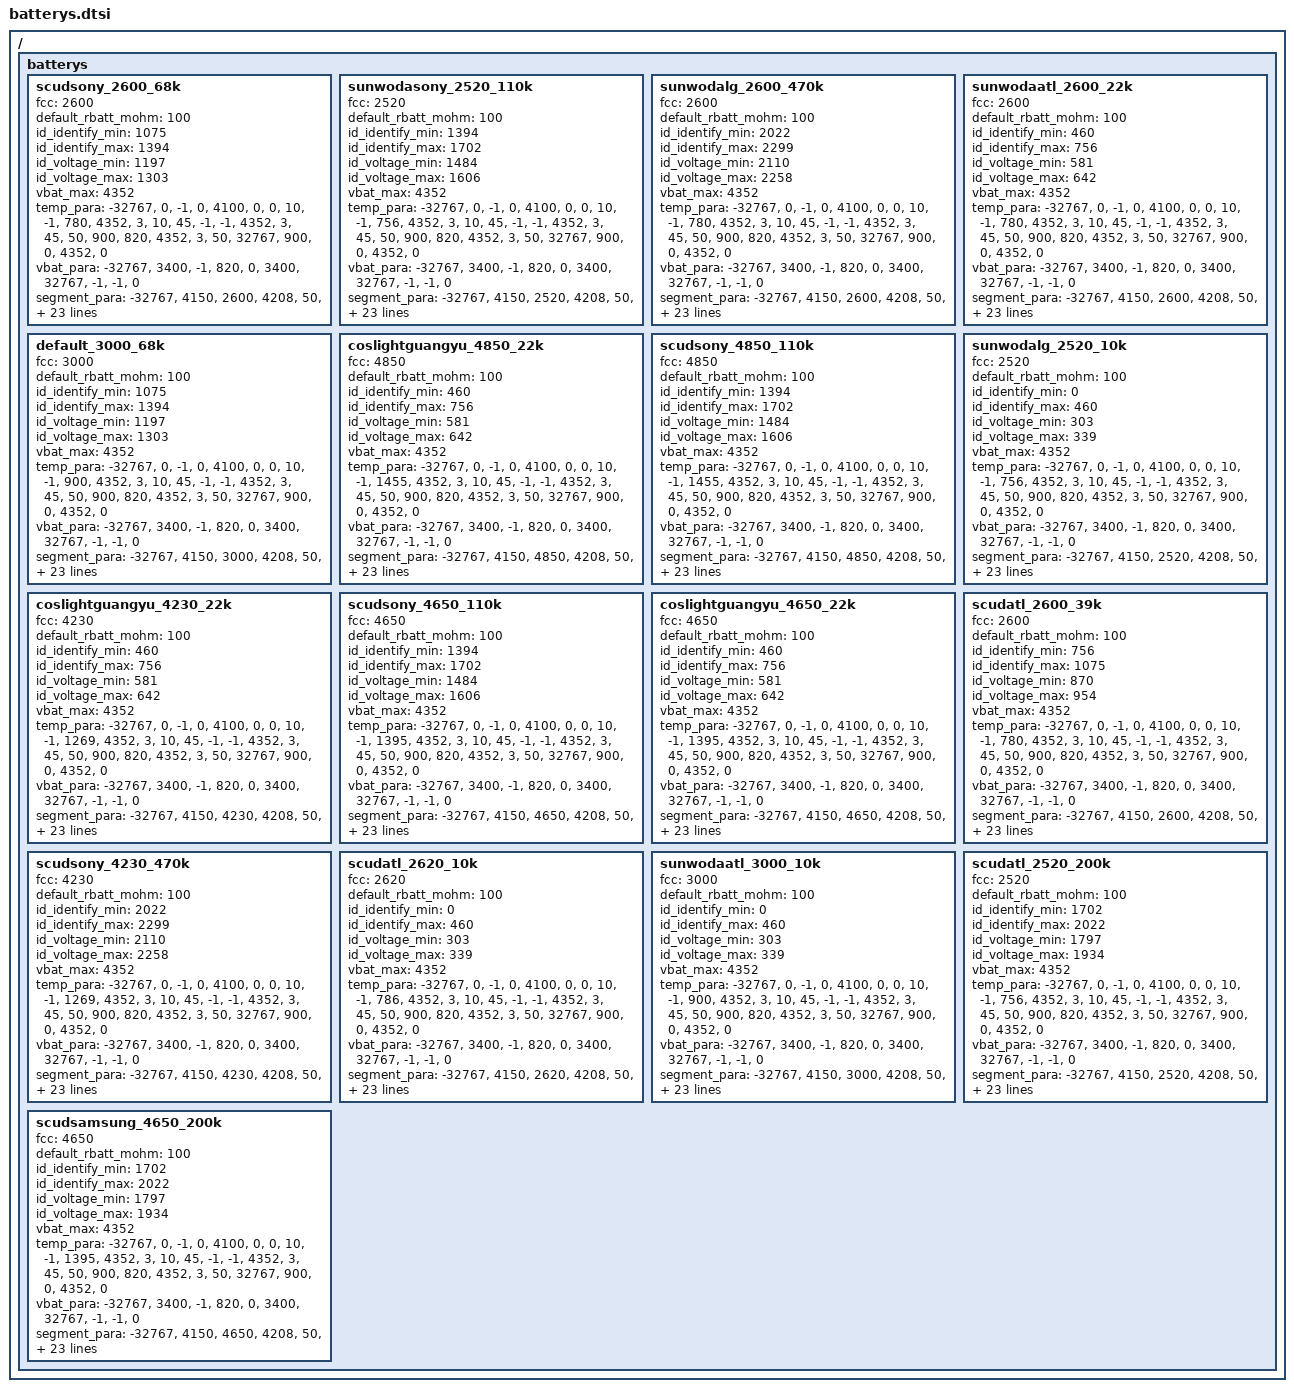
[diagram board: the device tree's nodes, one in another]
/* DO NOT EDIT - Automatically generated by python */
/ {
	batterys:batterys {
		scudsony_2600_68k:scudsony_2600_68k {
			fcc = <2600>;
			default_rbatt_mohm = <100>;
			id_identify_min = <1075>;
			id_identify_max = <1394>;
			id_voltage_min = <1197>;
			id_voltage_max = <1303>;
			vbat_max = <4352>;
			temp_para = 
						"-32767","0","-1","0","4100","0",
						"0","10","-1","780","4352","3",
						"10","45","-1","-1","4352","3",
						"45","50","900","820","4352","3",
						"50","32767","900","0","4352","0";
			vbat_para = 
						"-32767","3400","-1","820","0",
						"3400","32767","-1","-1","0";
			segment_para = 
						"-32767","4150","2600","4208","50",
						"4150","4450","1300","4352","0";
			batt_brand = "scudsony";
			fcc_temp = <2601 2604 2617 2680 2656 2621>;
			fcc_sf_x = <0 100 200 300 400 500>;
			fcc_sf_y = <100 96 94 92 90 88>;
			fcc_sf_cols = <6>;
			pc_sf_rows = <1>;
			pc_sf_cols = <1>;
			pc_sf_row_entries = <0>;
			pc_sf_percent = <100>;
			pc_sf_sf = <100>;
			rbatt_sf_rows = <28>;
			rbatt_sf_cols = <6>;
			rbatt_sf_percent = <100 95 90 85 80 75 70 65 60 55 50 45 40 35 30 25 20 15 10 9 8 7 6 5 4 3 2 1>;
			rbatt_sf_sf = <
			               1652 745 382 153 115 102
			               1652 746 382 154 116 102
			               1683 784 409 162 119 104
			               1668 786 433 171 123 106
			               1701 791 451 182 128 108
			               1666 773 463 194 135 111
			               1674 761 425 212 144 117
			               1691 774 416 218 157 124
			               1736 790 408 188 156 132
			               1790 809 404 166 129 109
			               1840 839 416 159 119 106
			               1922 860 435 164 121 107
			               2023 879 454 170 126 109
			               2134 923 475 175 132 113
			               2297 968 502 177 131 111
			               2515 1031 529 174 123 107
			               2838 1102 548 170 122 107
			               3317 1307 595 167 122 107
			               4148 1778 633 167 121 108
			               4298 1645 624 170 120 107
			               4906 1788 635 178 121 107
			               5835 2015 680 175 122 110
			               7110 2305 732 181 125 108
			               9342 2860 829 181 125 110
			               15676 4001 931 191 127 109
			               37262 7035 1267 216 132 106
			               79489 30656 1984 342 146 112
			               124988 50688 5514 592 295 122
			              >;
			pc_temp_ocv_rows = <29>;
			pc_temp_ocv_cols = <6>;
			pc_temp_ocv_percent = <100 95 90 85 80 75 70 65 60 55 50 45 40 35 30 25 20 15 10 9 8 7 6 5 4 3 2 1>;
			pc_temp_ocv_ocv = <
			                   4332 4326 4324 4319 4309 4303
			                   4244 4250 4255 4256 4247 4244
			                   4175 4191 4198 4199 4191 4189
			                   4109 4130 4143 4144 4137 4136
			                   4057 4075 4090 4093 4086 4086
			                   3993 4019 4039 4044 4039 4039
			                   3938 3967 3982 3999 3996 3997
			                   3888 3924 3938 3954 3955 3957
			                   3846 3885 3898 3907 3913 3916
			                   3811 3851 3863 3868 3870 3871
			                   3781 3823 3834 3839 3840 3842
			                   3760 3797 3811 3817 3818 3820
			                   3744 3775 3791 3799 3801 3801
			                   3728 3763 3775 3783 3786 3785
			                   3714 3751 3763 3768 3768 3765
			                   3698 3735 3749 3750 3745 3735
			                   3683 3705 3726 3728 3722 3712
			                   3665 3672 3694 3695 3692 3683
			                   3637 3650 3658 3670 3667 3658
			                   3629 3644 3654 3665 3663 3655
			                   3616 3637 3649 3660 3658 3651
			                   3604 3627 3642 3652 3651 3645
			                   3588 3613 3631 3640 3639 3632
			                   3565 3593 3614 3613 3610 3600
			                   3536 3563 3577 3569 3565 3557
			                   3489 3508 3523 3511 3508 3502
			                   3417 3429 3446 3442 3436 3432
			                   3321 3320 3345 3354 3342 3337
			                   3200 3200 3200 3200 3200 3200
			                  >;
		};
		sunwodasony_2520_110k:sunwodasony_2520_110k {
			fcc = <2520>;
			default_rbatt_mohm = <100>;
			id_identify_min = <1394>;
			id_identify_max = <1702>;
			id_voltage_min = <1484>;
			id_voltage_max = <1606>;
			vbat_max = <4352>;
			temp_para = 
						"-32767","0","-1","0","4100","0",
						"0","10","-1","756","4352","3",
						"10","45","-1","-1","4352","3",
						"45","50","900","820","4352","3",
						"50","32767","900","0","4352","0";
			vbat_para = 
						"-32767","3400","-1","820","0",
						"3400","32767","-1","-1","0";
			segment_para = 
						"-32767","4150","2520","4208","50",
						"4150","4450","1260","4352","0";
			batt_brand = "sunwodasony";
			fcc_temp = <2508 2496 2507 2552 2518 2497>;
			fcc_sf_x = <0 100 200 300 400 500>;
			fcc_sf_y = <100 96 94 92 90 88>;
			fcc_sf_cols = <6>;
			pc_sf_rows = <1>;
			pc_sf_cols = <1>;
			pc_sf_row_entries = <0>;
			pc_sf_percent = <100>;
			pc_sf_sf = <100>;
			rbatt_sf_rows = <28>;
			rbatt_sf_cols = <6>;
			rbatt_sf_percent = <100 95 90 85 80 75 70 65 60 55 50 45 40 35 30 25 20 15 10 9 8 7 6 5 4 3 2 1>;
			rbatt_sf_sf = <
			               1431 634 335 135 107 96
			               1431 634 335 135 107 96
			               1446 667 357 142 111 98
			               1443 684 380 150 115 99
			               1460 706 409 161 120 101
			               1403 664 424 176 125 104
			               1408 633 386 189 134 109
			               1445 634 367 194 152 119
			               1477 632 351 166 145 120
			               1485 661 344 144 117 103
			               1572 694 350 140 112 99
			               1658 732 367 143 114 100
			               1752 758 387 148 117 102
			               1856 778 405 153 123 105
			               1986 801 429 152 119 100
			               2149 837 452 149 113 100
			               2401 842 448 144 112 100
			               2790 999 435 143 112 100
			               3596 1377 527 150 113 100
			               3742 1363 527 143 114 100
			               3881 1236 529 141 113 102
			               4020 1317 546 145 118 103
			               3962 1387 558 146 117 100
			               4692 1499 564 145 112 100
			               5804 1635 574 149 115 101
			               7150 1955 606 151 116 103
			               9204 2435 686 159 116 104
			               12389 3390 819 171 123 113
			              >;
			pc_temp_ocv_rows = <29>;
			pc_temp_ocv_cols = <6>;
			pc_temp_ocv_percent = <100 95 90 85 80 75 70 65 60 55 50 45 40 35 30 25 20 15 10 9 8 7 6 5 4 3 2 1>;
			pc_temp_ocv_ocv = <
			                   4337 4323 4320 4325 4310 4303
			                   4261 4257 4257 4265 4250 4245
			                   4195 4199 4201 4209 4195 4191
			                   4134 4143 4146 4155 4142 4138
			                   4083 4092 4095 4102 4092 4088
			                   4016 4031 4046 4054 4045 4042
			                   3960 3977 3989 4006 4002 3999
			                   3915 3933 3942 3961 3962 3960
			                   3873 3891 3902 3914 3917 3916
			                   3828 3858 3867 3876 3873 3873
			                   3796 3830 3837 3847 3845 3844
			                   3771 3807 3814 3824 3823 3822
			                   3753 3787 3795 3805 3804 3803
			                   3738 3770 3779 3789 3789 3787
			                   3727 3756 3768 3772 3771 3761
			                   3716 3743 3757 3755 3747 3735
			                   3706 3714 3734 3732 3725 3713
			                   3691 3695 3700 3703 3694 3681
			                   3661 3676 3676 3678 3672 3662
			                   3658 3670 3671 3675 3669 3658
			                   3656 3661 3667 3671 3666 3655
			                   3654 3652 3661 3665 3660 3648
			                   3628 3638 3650 3653 3646 3631
			                   3597 3615 3626 3625 3615 3598
			                   3561 3576 3586 3581 3571 3555
			                   3510 3523 3532 3525 3516 3501
			                   3441 3451 3462 3454 3446 3432
			                   3345 3356 3365 3356 3350 3339
			                   3200 3200 3200 3200 3200 3200
			                  >;
		};
		sunwodalg_2600_470k:sunwodalg_2600_470k {
			fcc = <2600>;
			default_rbatt_mohm = <100>;
			id_identify_min = <2022>;
			id_identify_max = <2299>;
			id_voltage_min = <2110>;
			id_voltage_max = <2258>;
			vbat_max = <4352>;
			temp_para = 
						"-32767","0","-1","0","4100","0",
						"0","10","-1","780","4352","3",
						"10","45","-1","-1","4352","3",
						"45","50","900","820","4352","3",
						"50","32767","900","0","4352","0";
			vbat_para = 
						"-32767","3400","-1","820","0",
						"3400","32767","-1","-1","0";
			segment_para = 
						"-32767","4150","2600","4208","50",
						"4150","4450","1300","4352","0";
			batt_brand = "sunwodalg";
			fcc_temp = <2702 2691 2691 2724 2698 2680>;
			fcc_sf_x = <0 100 200 300 400 500>;
			fcc_sf_y = <100 96 94 92 90 88>;
			fcc_sf_cols = <6>;
			pc_sf_rows = <1>;
			pc_sf_cols = <1>;
			pc_sf_row_entries = <0>;
			pc_sf_percent = <100>;
			pc_sf_sf = <100>;
			rbatt_sf_rows = <28>;
			rbatt_sf_cols = <6>;
			rbatt_sf_percent = <100 95 90 85 80 75 70 65 60 55 50 45 40 35 30 25 20 15 10 9 8 7 6 5 4 3 2 1>;
			rbatt_sf_sf = <
			               2513 1705 766 152 108 91
			               2507 1700 766 152 108 91
			               2386 1589 761 155 110 93
			               2309 1510 759 161 114 95
			               2278 1493 780 168 118 97
			               2200 1433 792 176 124 100
			               2196 1411 780 190 130 104
			               2196 1407 790 211 143 110
			               2218 1409 771 206 153 120
			               2261 1428 766 169 134 115
			               2323 1469 790 154 112 94
			               2406 1530 838 158 114 96
			               2501 1609 904 164 121 101
			               2617 1699 986 170 127 106
			               2759 1806 1082 175 123 101
			               2933 1927 1191 178 118 94
			               3161 2055 1322 179 118 96
			               3477 2238 1484 180 116 94
			               7285 3492 1756 188 122 98
			               7742 3763 1907 189 120 98
			               8270 4120 2106 198 124 99
			               8805 4434 2276 209 127 100
			               9397 4816 2552 219 127 99
			               10043 5214 2774 253 128 100
			               10774 5548 3094 491 142 104
			               11603 6041 3283 736 297 196
			               12596 6698 3576 549 371 166
			               13951 7437 4010 582 217 108
			              >;
			pc_temp_ocv_rows = <29>;
			pc_temp_ocv_cols = <6>;
			pc_temp_ocv_percent = <100 95 90 85 80 75 70 65 60 55 50 45 40 35 30 25 20 15 10 9 8 7 6 5 4 3 2 1>;
			pc_temp_ocv_ocv = <
			                   4334 4328 4325 4321 4310 4304
			                   4241 4242 4246 4258 4248 4245
			                   4174 4176 4183 4202 4192 4191
			                   4113 4119 4127 4148 4139 4138
			                   4057 4071 4077 4097 4088 4088
			                   3988 4009 4026 4049 4041 4040
			                   3939 3957 3975 4003 3998 3997
			                   3897 3914 3933 3964 3959 3958
			                   3864 3875 3887 3919 3919 3921
			                   3838 3844 3849 3872 3874 3878
			                   3820 3823 3823 3839 3838 3839
			                   3804 3807 3805 3816 3815 3816
			                   3792 3796 3794 3797 3798 3797
			                   3779 3786 3784 3782 3782 3782
			                   3765 3775 3774 3770 3767 3761
			                   3750 3760 3758 3756 3750 3738
			                   3735 3737 3737 3733 3729 3716
			                   3714 3714 3709 3692 3691 3682
			                   3682 3687 3680 3681 3675 3664
			                   3674 3681 3675 3679 3673 3662
			                   3667 3677 3669 3675 3671 3660
			                   3657 3671 3660 3668 3667 3657
			                   3643 3662 3650 3650 3658 3647
			                   3622 3646 3634 3614 3632 3620
			                   3590 3615 3611 3575 3589 3580
			                   3545 3568 3568 3533 3541 3532
			                   3478 3502 3500 3460 3478 3465
			                   3379 3400 3398 3348 3374 3364
			                   3200 3200 3200 3200 3200 3200
			                  >;
		};
		sunwodaatl_2600_22k:sunwodaatl_2600_22k {
			fcc = <2600>;
			default_rbatt_mohm = <100>;
			id_identify_min = <460>;
			id_identify_max = <756>;
			id_voltage_min = <581>;
			id_voltage_max = <642>;
			vbat_max = <4352>;
			temp_para = 
						"-32767","0","-1","0","4100","0",
						"0","10","-1","780","4352","3",
						"10","45","-1","-1","4352","3",
						"45","50","900","820","4352","3",
						"50","32767","900","0","4352","0";
			vbat_para = 
						"-32767","3400","-1","820","0",
						"3400","32767","-1","-1","0";
			segment_para = 
						"-32767","4150","2600","4208","50",
						"4150","4450","1300","4352","0";
			batt_brand = "sunwodaatl";
			fcc_temp = <2647 2638 2645 2649 2642 2628>;
			fcc_sf_x = <0 100 200 300 400 500>;
			fcc_sf_y = <100 96 94 92 90 88>;
			fcc_sf_cols = <6>;
			pc_sf_rows = <1>;
			pc_sf_cols = <1>;
			pc_sf_row_entries = <0>;
			pc_sf_percent = <100>;
			pc_sf_sf = <100>;
			rbatt_sf_rows = <28>;
			rbatt_sf_cols = <6>;
			rbatt_sf_percent = <100 95 90 85 80 75 70 65 60 55 50 45 40 35 30 25 20 15 10 9 8 7 6 5 4 3 2 1>;
			rbatt_sf_sf = <
			               2648 1691 662 174 126 104
			               2646 1690 663 174 126 104
			               2521 1634 677 177 127 105
			               2409 1568 686 181 129 106
			               2359 1550 703 187 132 108
			               2271 1473 719 195 137 110
			               2266 1449 691 208 143 115
			               2255 1439 690 227 155 120
			               2263 1437 671 222 164 128
			               2291 1448 661 182 136 110
			               2336 1481 671 169 124 106
			               2406 1528 697 171 125 105
			               2497 1595 738 176 129 109
			               2612 1679 795 181 136 114
			               2761 1783 866 183 135 114
			               2943 1918 952 184 125 104
			               3183 2072 1070 185 127 105
			               3541 2275 1254 191 130 106
			               6783 2928 1296 197 134 109
			               7566 3253 1404 198 133 110
			               8348 3606 1549 204 135 110
			               9164 4006 1722 218 137 111
			               10138 4535 1956 222 142 113
			               11173 5084 2218 224 143 112
			               12392 5727 2544 227 141 111
			               13841 6531 2941 248 148 111
			               15742 7595 3512 304 159 114
			               16534 9284 4272 677 220 173
			              >;
			pc_temp_ocv_rows = <29>;
			pc_temp_ocv_cols = <6>;
			pc_temp_ocv_percent = <100 95 90 85 80 75 70 65 60 55 50 45 40 35 30 25 20 15 10 9 8 7 6 5 4 3 2 1>;
			pc_temp_ocv_ocv = <
			                   4330 4323 4322 4317 4310 4303
			                   4233 4237 4246 4252 4246 4241
			                   4163 4172 4185 4195 4190 4184
			                   4099 4112 4130 4140 4135 4130
			                   4042 4062 4078 4088 4083 4078
			                   3975 3997 4027 4040 4036 4030
			                   3931 3949 3973 3994 3991 3987
			                   3890 3908 3931 3955 3952 3947
			                   3857 3871 3889 3911 3912 3909
			                   3831 3841 3852 3864 3864 3860
			                   3812 3819 3823 3833 3833 3831
			                   3798 3803 3803 3812 3811 3809
			                   3786 3792 3790 3794 3794 3791
			                   3774 3783 3781 3780 3779 3777
			                   3761 3773 3771 3767 3765 3760
			                   3746 3759 3758 3752 3745 3732
			                   3730 3737 3738 3732 3724 3711
			                   3709 3710 3709 3702 3697 3685
			                   3678 3683 3675 3676 3670 3659
			                   3670 3677 3670 3673 3667 3656
			                   3662 3671 3666 3670 3664 3653
			                   3651 3664 3660 3664 3660 3648
			                   3640 3656 3652 3655 3653 3640
			                   3623 3642 3636 3634 3636 3620
			                   3598 3617 3605 3592 3597 3581
			                   3559 3571 3553 3535 3543 3527
			                   3498 3503 3482 3459 3472 3456
			                   3400 3402 3374 3359 3373 3355
			                   3200 3200 3200 3200 3200 3200
			                  >;
		};
		default_3000_68k:default_3000_68k {
			fcc = <3000>;
			default_rbatt_mohm = <100>;
			id_identify_min = <1075>;
			id_identify_max = <1394>;
			id_voltage_min = <1197>;
			id_voltage_max = <1303>;
			vbat_max = <4352>;
			temp_para = 
						"-32767","0","-1","0","4100","0",
						"0","10","-1","900","4352","3",
						"10","45","-1","-1","4352","3",
						"45","50","900","820","4352","3",
						"50","32767","900","0","4352","0";
			vbat_para = 
						"-32767","3400","-1","820","0",
						"3400","32767","-1","-1","0";
			segment_para = 
						"-32767","4150","3000","4208","50",
						"4150","4450","1500","4352","0";
			batt_brand = "default";
			fcc_temp = <3007 3010 3005 3022 3018 2996>;
			fcc_sf_x = <0 100 200 300 400 500>;
			fcc_sf_y = <100 96 94 92 90 88>;
			fcc_sf_cols = <6>;
			pc_sf_rows = <1>;
			pc_sf_cols = <1>;
			pc_sf_row_entries = <0>;
			pc_sf_percent = <100>;
			pc_sf_sf = <100>;
			rbatt_sf_rows = <28>;
			rbatt_sf_cols = <6>;
			rbatt_sf_percent = <100 95 90 85 80 75 70 65 60 55 50 45 40 35 30 25 20 15 10 9 8 7 6 5 4 3 2 1>;
			rbatt_sf_sf = <
			               1971 888 459 150 121 112
			               1970 888 459 150 121 112
			               1839 913 472 152 123 113
			               1713 920 490 156 125 115
			               1676 943 504 161 128 116
			               1543 895 532 170 132 118
			               1517 837 489 181 137 121
			               1515 831 470 199 148 127
			               1516 824 448 200 160 137
			               1531 823 437 155 129 116
			               1611 847 434 150 123 114
			               1714 921 422 151 124 115
			               1830 1023 448 155 128 117
			               1954 1148 499 158 134 120
			               2083 1284 576 159 132 122
			               2230 1422 664 157 125 114
			               2410 1589 766 154 122 113
			               2657 1792 883 159 123 113
			               3658 1996 983 161 128 117
			               4481 2141 924 161 129 119
			               4966 2392 991 159 127 116
			               5434 2660 1095 166 127 116
			               5970 2933 1229 168 130 118
			               6541 3252 1382 172 129 118
			               7189 3594 1509 175 129 117
			               7980 3994 1669 183 132 119
			               8915 4511 1946 202 136 120
			               10198 5252 2365 279 143 122
			              >;
			pc_temp_ocv_rows = <29>;
			pc_temp_ocv_cols = <6>;
			pc_temp_ocv_percent = <100 95 90 85 80 75 70 65 60 55 50 45 40 35 30 25 20 15 10 9 8 7 6 5 4 3 2 1>;
			pc_temp_ocv_ocv = <
			                   4326 4325 4322 4317 4311 4305
			                   4224 4239 4246 4254 4249 4245
			                   4156 4178 4186 4196 4193 4189
			                   4090 4121 4132 4142 4138 4134
			                   4041 4073 4082 4090 4086 4083
			                   3967 4011 4034 4042 4038 4035
			                   3917 3951 3976 3997 3994 3991
			                   3878 3907 3929 3957 3955 3952
			                   3843 3868 3885 3914 3915 3914
			                   3815 3833 3849 3865 3865 3863
			                   3801 3808 3821 3835 3835 3834
			                   3788 3796 3797 3813 3812 3812
			                   3774 3786 3785 3794 3794 3793
			                   3760 3776 3777 3779 3780 3778
			                   3746 3761 3768 3767 3765 3762
			                   3732 3740 3753 3754 3747 3737
			                   3716 3720 3730 3734 3726 3716
			                   3699 3702 3700 3705 3699 3688
			                   3671 3684 3677 3680 3674 3664
			                   3662 3677 3673 3679 3672 3662
			                   3653 3671 3669 3677 3671 3660
			                   3640 3664 3664 3673 3668 3657
			                   3626 3654 3658 3667 3663 3652
			                   3606 3637 3645 3650 3650 3638
			                   3578 3609 3618 3611 3614 3604
			                   3540 3566 3571 3554 3560 3553
			                   3482 3500 3502 3478 3490 3486
			                   3389 3399 3403 3363 3387 3387
			                   3200 3200 3200 3200 3200 3200
			                  >;
		};
		coslightguangyu_4850_22k:coslightguangyu_4850_22k {
			fcc = <4850>;
			default_rbatt_mohm = <100>;
			id_identify_min = <460>;
			id_identify_max = <756>;
			id_voltage_min = <581>;
			id_voltage_max = <642>;
			vbat_max = <4352>;
			temp_para = 
						"-32767","0","-1","0","4100","0",
						"0","10","-1","1455","4352","3",
						"10","45","-1","-1","4352","3",
						"45","50","900","820","4352","3",
						"50","32767","900","0","4352","0";
			vbat_para = 
						"-32767","3400","-1","820","0",
						"3400","32767","-1","-1","0";
			segment_para = 
						"-32767","4150","4850","4208","50",
						"4150","4450","2425","4352","0";
			batt_brand = "coslightguangyu";
			fcc_temp = <5059 5069 5068 5086 5083 5045>;
			fcc_sf_x = <0 100 200 300 400 500>;
			fcc_sf_y = <100 96 94 92 90 88>;
			fcc_sf_cols = <6>;
			pc_sf_rows = <1>;
			pc_sf_cols = <1>;
			pc_sf_row_entries = <0>;
			pc_sf_percent = <100>;
			pc_sf_sf = <100>;
			rbatt_sf_rows = <28>;
			rbatt_sf_cols = <6>;
			rbatt_sf_percent = <100 95 90 85 80 75 70 65 60 55 50 45 40 35 30 25 20 15 10 9 8 7 6 5 4 3 2 1>;
			rbatt_sf_sf = <
			               1395 696 333 119 103 102
			               1391 696 333 119 103 102
			               1297 699 339 119 104 103
			               1210 694 343 121 105 103
			               1178 699 348 124 106 104
			               1053 677 378 129 108 105
			               1008 586 313 132 111 107
			               1000 597 303 133 112 108
			               988 591 302 120 105 104
			               1011 597 298 116 104 103
			               1051 633 298 117 104 103
			               1098 687 307 118 104 104
			               1148 751 330 121 106 104
			               1200 820 366 123 107 106
			               1257 893 412 119 105 104
			               1324 963 464 117 104 103
			               1406 1039 531 120 104 103
			               1505 1132 624 122 105 104
			               2041 1001 494 119 105 105
			               2186 1079 529 120 106 105
			               2309 1154 568 121 107 107
			               2488 1257 615 121 107 107
			               2671 1370 664 120 107 104
			               2887 1496 718 121 105 105
			               3140 1643 783 123 107 105
			               3461 1863 883 126 108 105
			               3883 2147 1062 142 111 109
			               4391 2470 1282 243 143 126
			              >;
			pc_temp_ocv_rows = <29>;
			pc_temp_ocv_cols = <6>;
			pc_temp_ocv_percent = <100 95 90 85 80 75 70 65 60 55 50 45 40 35 30 25 20 15 10 9 8 7 6 5 4 3 2 1>;
			pc_temp_ocv_ocv = <
			                   4342 4341 4338 4332 4328 4322
			                   4241 4255 4262 4271 4268 4264
			                   4174 4191 4203 4213 4211 4207
			                   4111 4136 4150 4158 4156 4153
			                   4067 4087 4098 4106 4102 4100
			                   3980 4028 4051 4057 4051 4050
			                   3924 3943 3969 3995 4000 4003
			                   3884 3903 3922 3949 3955 3956
			                   3845 3863 3885 3903 3905 3905
			                   3820 3830 3850 3868 3868 3869
			                   3804 3810 3821 3840 3841 3841
			                   3790 3797 3801 3818 3818 3818
			                   3776 3785 3787 3799 3800 3799
			                   3763 3773 3777 3782 3783 3781
			                   3750 3759 3765 3765 3760 3754
			                   3736 3742 3750 3748 3739 3729
			                   3721 3723 3731 3729 3722 3710
			                   3701 3709 3707 3705 3698 3687
			                   3672 3690 3688 3688 3681 3670
			                   3662 3685 3685 3686 3679 3668
			                   3649 3677 3680 3684 3677 3666
			                   3634 3666 3672 3678 3672 3662
			                   3616 3649 3658 3664 3657 3649
			                   3592 3624 3633 3632 3627 3619
			                   3561 3588 3596 3591 3586 3579
			                   3520 3542 3545 3538 3535 3530
			                   3466 3480 3479 3470 3468 3466
			                   3379 3384 3384 3379 3372 3375
			                   3200 3200 3200 3200 3200 3200
			                  >;
		};
		scudsony_4850_110k:scudsony_4850_110k {
			fcc = <4850>;
			default_rbatt_mohm = <100>;
			id_identify_min = <1394>;
			id_identify_max = <1702>;
			id_voltage_min = <1484>;
			id_voltage_max = <1606>;
			vbat_max = <4352>;
			temp_para = 
						"-32767","0","-1","0","4100","0",
						"0","10","-1","1455","4352","3",
						"10","45","-1","-1","4352","3",
						"45","50","900","820","4352","3",
						"50","32767","900","0","4352","0";
			vbat_para = 
						"-32767","3400","-1","820","0",
						"3400","32767","-1","-1","0";
			segment_para = 
						"-32767","4150","4850","4208","50",
						"4150","4450","2425","4352","0";
			batt_brand = "scudsony";
			fcc_temp = <4975 4906 4919 4975 4952 4965>;
			fcc_sf_x = <0 100 200 300 400 500>;
			fcc_sf_y = <100 96 94 92 90 88>;
			fcc_sf_cols = <6>;
			pc_sf_rows = <1>;
			pc_sf_cols = <1>;
			pc_sf_row_entries = <0>;
			pc_sf_percent = <100>;
			pc_sf_sf = <100>;
			rbatt_sf_rows = <28>;
			rbatt_sf_cols = <6>;
			rbatt_sf_percent = <100 95 90 85 80 75 70 65 60 55 50 45 40 35 30 25 20 15 10 9 8 7 6 5 4 3 2 1>;
			rbatt_sf_sf = <
			               1377 867 425 128 90 80
			               1376 867 425 128 90 80
			               1339 878 433 130 91 81
			               1301 879 438 132 93 81
			               1275 871 446 137 95 83
			               1256 856 452 143 98 84
			               1249 849 448 151 103 86
			               1251 842 442 154 109 90
			               1266 856 442 144 105 91
			               1283 876 442 135 94 84
			               1311 892 451 133 94 83
			               1342 923 470 136 96 85
			               1380 947 498 142 98 86
			               1434 977 521 146 101 87
			               1502 1018 550 149 101 87
			               1596 1077 577 149 99 86
			               1729 1145 612 150 99 87
			               1940 1249 666 155 100 87
			               3752 1781 773 150 102 87
			               4074 1920 806 151 101 88
			               4439 2049 844 152 102 90
			               4911 2222 895 154 103 89
			               5585 2450 980 157 104 88
			               6486 2695 1068 157 103 88
			               7511 3049 1155 157 104 91
			               8846 3580 1315 163 107 90
			               10180 4481 1557 176 109 93
			               11515 5722 1971 192 119 100
			              >;
			pc_temp_ocv_rows = <29>;
			pc_temp_ocv_cols = <6>;
			pc_temp_ocv_percent = <100 95 90 85 80 75 70 65 60 55 50 45 40 35 30 25 20 15 10 9 8 7 6 5 4 3 2 1>;
			pc_temp_ocv_ocv = <
			                   4337 4336 4334 4325 4318 4323
			                   4219 4230 4246 4253 4250 4256
			                   4145 4166 4183 4195 4193 4199
			                   4080 4108 4126 4141 4140 4146
			                   4019 4051 4074 4090 4089 4095
			                   3964 3994 4024 4042 4042 4047
			                   3914 3944 3974 3997 3998 4002
			                   3871 3897 3926 3953 3956 3961
			                   3837 3861 3885 3908 3912 3919
			                   3805 3830 3849 3868 3871 3876
			                   3778 3803 3820 3838 3842 3845
			                   3751 3782 3798 3815 3819 3821
			                   3728 3762 3781 3797 3801 3802
			                   3708 3743 3767 3781 3785 3785
			                   3690 3723 3753 3766 3766 3762
			                   3672 3704 3736 3748 3744 3733
			                   3653 3678 3711 3725 3722 3711
			                   3624 3645 3675 3696 3695 3685
			                   3585 3615 3635 3671 3671 3661
			                   3570 3609 3629 3667 3669 3658
			                   3550 3599 3622 3663 3665 3655
			                   3525 3587 3612 3656 3659 3649
			                   3494 3573 3600 3643 3646 3634
			                   3455 3548 3581 3616 3617 3605
			                   3411 3510 3545 3575 3573 3563
			                   3358 3455 3493 3520 3519 3509
			                   3306 3385 3425 3450 3448 3440
			                   3253 3299 3334 3354 3351 3346
			                   3200 3200 3200 3200 3200 3200
			                  >;
		};
		sunwodalg_2520_10k:sunwodalg_2520_10k {
			fcc = <2520>;
			default_rbatt_mohm = <100>;
			id_identify_min = <0>;
			id_identify_max = <460>;
			id_voltage_min = <303>;
			id_voltage_max = <339>;
			vbat_max = <4352>;
			temp_para = 
						"-32767","0","-1","0","4100","0",
						"0","10","-1","756","4352","3",
						"10","45","-1","-1","4352","3",
						"45","50","900","820","4352","3",
						"50","32767","900","0","4352","0";
			vbat_para = 
						"-32767","3400","-1","820","0",
						"3400","32767","-1","-1","0";
			segment_para = 
						"-32767","4150","2520","4208","50",
						"4150","4450","1260","4352","0";
			batt_brand = "sunwodalg";
			fcc_temp = <2610 2620 2609 2627 2614 2596>;
			fcc_sf_x = <0 100 200 300 400 500>;
			fcc_sf_y = <100 96 94 92 90 88>;
			fcc_sf_cols = <6>;
			pc_sf_rows = <1>;
			pc_sf_cols = <1>;
			pc_sf_row_entries = <0>;
			pc_sf_percent = <100>;
			pc_sf_sf = <100>;
			rbatt_sf_rows = <28>;
			rbatt_sf_cols = <6>;
			rbatt_sf_percent = <100 95 90 85 80 75 70 65 60 55 50 45 40 35 30 25 20 15 10 9 8 7 6 5 4 3 2 1>;
			rbatt_sf_sf = <
			               2740 1453 792 153 108 89
			               2731 1450 792 153 108 89
			               2499 1398 785 158 109 90
			               2401 1354 773 161 113 92
			               2361 1377 810 167 117 95
			               2217 1343 800 179 122 98
			               2210 1281 777 192 128 102
			               2210 1279 778 216 141 108
			               2225 1275 751 212 153 115
			               2267 1286 739 169 137 111
			               2336 1331 763 157 112 92
			               2423 1399 810 160 114 94
			               2525 1484 882 165 119 99
			               2652 1582 970 170 125 104
			               2802 1698 1070 177 121 101
			               2983 1839 1186 179 116 93
			               3211 2005 1327 181 117 92
			               3524 2215 1517 185 117 93
			               7091 3144 1638 189 116 96
			               7599 3414 1766 193 121 98
			               8195 3701 1941 201 124 99
			               8818 4107 2126 219 125 99
			               9496 4458 2352 279 130 96
			               10249 4851 2702 482 171 128
			               11138 5513 3091 285 296 158
			               11756 5762 2865 564 201 145
			               13101 5878 3493 286 178 112
			               14292 7215 4087 740 144 111
			              >;
			pc_temp_ocv_rows = <29>;
			pc_temp_ocv_cols = <6>;
			pc_temp_ocv_percent = <100 95 90 85 80 75 70 65 60 55 50 45 40 35 30 25 20 15 10 9 8 7 6 5 4 3 2 1>;
			pc_temp_ocv_ocv = <
			                   4322 4325 4315 4315 4307 4302
			                   4235 4246 4242 4254 4247 4242
			                   4167 4183 4182 4199 4192 4188
			                   4115 4125 4125 4145 4140 4135
			                   4065 4082 4081 4095 4089 4085
			                   3982 4023 4027 4048 4042 4038
			                   3934 3958 3972 4002 3998 3995
			                   3893 3914 3929 3963 3960 3956
			                   3858 3874 3884 3918 3920 3918
			                   3834 3841 3846 3870 3875 3875
			                   3817 3819 3820 3839 3839 3838
			                   3802 3804 3803 3817 3816 3815
			                   3789 3793 3793 3798 3798 3797
			                   3778 3781 3784 3783 3783 3782
			                   3765 3768 3772 3771 3767 3761
			                   3751 3753 3756 3757 3751 3738
			                   3736 3736 3733 3733 3729 3715
			                   3715 3716 3710 3697 3693 3684
			                   3684 3688 3685 3682 3676 3665
			                   3675 3684 3680 3680 3674 3663
			                   3667 3677 3674 3677 3672 3661
			                   3657 3671 3665 3670 3669 3658
			                   3643 3660 3652 3654 3660 3649
			                   3625 3638 3636 3629 3636 3623
			                   3601 3614 3617 3583 3601 3584
			                   3546 3572 3557 3533 3547 3533
			                   3480 3489 3484 3446 3475 3463
			                   3371 3379 3374 3338 3371 3366
			                   3200 3200 3200 3200 3200 3200
			                  >;
		};
		coslightguangyu_4230_22k:coslightguangyu_4230_22k {
			fcc = <4230>;
			default_rbatt_mohm = <100>;
			id_identify_min = <460>;
			id_identify_max = <756>;
			id_voltage_min = <581>;
			id_voltage_max = <642>;
			vbat_max = <4352>;
			temp_para = 
						"-32767","0","-1","0","4100","0",
						"0","10","-1","1269","4352","3",
						"10","45","-1","-1","4352","3",
						"45","50","900","820","4352","3",
						"50","32767","900","0","4352","0";
			vbat_para = 
						"-32767","3400","-1","820","0",
						"3400","32767","-1","-1","0";
			segment_para = 
						"-32767","4150","4230","4208","50",
						"4150","4450","2115","4352","0";
			batt_brand = "coslightguangyu";
			fcc_temp = <4298 4298 4299 4316 4308 4281>;
			fcc_sf_x = <0 100 200 300 400 500>;
			fcc_sf_y = <100 96 94 92 90 88>;
			fcc_sf_cols = <6>;
			pc_sf_rows = <1>;
			pc_sf_cols = <1>;
			pc_sf_row_entries = <0>;
			pc_sf_percent = <100>;
			pc_sf_sf = <100>;
			rbatt_sf_rows = <28>;
			rbatt_sf_cols = <6>;
			rbatt_sf_percent = <100 95 90 85 80 75 70 65 60 55 50 45 40 35 30 25 20 15 10 9 8 7 6 5 4 3 2 1>;
			rbatt_sf_sf = <
			               1127 1127 585 130 100 92
			               1127 1127 585 130 100 92
			               1092 1092 579 128 100 93
			               1052 1052 566 130 101 93
			               1049 1049 588 132 102 94
			               945 945 563 141 108 95
			               905 905 528 135 105 96
			               890 890 535 148 111 98
			               868 868 508 148 116 101
			               872 872 500 126 102 95
			               891 891 510 121 99 93
			               917 917 531 121 99 94
			               946 946 559 123 100 95
			               985 985 597 125 103 96
			               1032 1032 641 126 103 96
			               1089 1089 698 125 99 93
			               1153 1153 770 126 99 93
			               1234 1234 864 130 100 93
			               1362 1362 825 127 102 95
			               1474 1474 881 126 103 96
			               1608 1608 975 129 105 96
			               1744 1744 1091 130 103 97
			               1896 1896 1195 132 105 98
			               2052 2052 1303 130 103 97
			               2222 2222 1388 131 103 97
			               2390 2390 1547 134 103 97
			               2659 2659 1773 138 105 97
			               3037 3037 2090 160 112 100
			              >;
			pc_temp_ocv_rows = <29>;
			pc_temp_ocv_cols = <6>;
			pc_temp_ocv_percent = <100 95 90 85 80 75 70 65 60 55 50 45 40 35 30 25 20 15 10 9 8 7 6 5 4 3 2 1>;
			pc_temp_ocv_ocv = <
			                   4331 4331 4333 4328 4323 4317
			                   4241 4241 4248 4260 4259 4255
			                   4178 4178 4187 4203 4203 4199
			                   4122 4122 4130 4150 4149 4145
			                   4080 4080 4088 4098 4097 4095
			                   3998 3998 4023 4057 4052 4047
			                   3944 3944 3964 3991 3996 4002
			                   3904 3904 3929 3959 3964 3961
			                   3865 3865 3882 3919 3922 3920
			                   3839 3839 3846 3871 3873 3872
			                   3821 3821 3821 3840 3842 3842
			                   3807 3807 3806 3818 3819 3819
			                   3795 3795 3795 3800 3801 3800
			                   3785 3785 3786 3786 3786 3784
			                   3773 3773 3776 3772 3770 3766
			                   3760 3760 3763 3758 3748 3736
			                   3740 3740 3744 3738 3728 3715
			                   3716 3716 3718 3712 3704 3692
			                   3693 3693 3689 3690 3682 3670
			                   3688 3688 3685 3688 3681 3669
			                   3683 3683 3681 3686 3679 3667
			                   3677 3677 3676 3683 3676 3664
			                   3666 3666 3667 3678 3671 3657
			                   3647 3647 3650 3661 3652 3635
			                   3615 3615 3618 3622 3614 3596
			                   3565 3565 3570 3569 3563 3545
			                   3496 3496 3502 3499 3494 3477
			                   3396 3396 3404 3397 3394 3377
			                   3200 3200 3200 3200 3200 3200
			                  >;
		};
		scudsony_4650_110k:scudsony_4650_110k {
			fcc = <4650>;
			default_rbatt_mohm = <100>;
			id_identify_min = <1394>;
			id_identify_max = <1702>;
			id_voltage_min = <1484>;
			id_voltage_max = <1606>;
			vbat_max = <4352>;
			temp_para = 
						"-32767","0","-1","0","4100","0",
						"0","10","-1","1395","4352","3",
						"10","45","-1","-1","4352","3",
						"45","50","900","820","4352","3",
						"50","32767","900","0","4352","0";
			vbat_para = 
						"-32767","3400","-1","820","0",
						"3400","32767","-1","-1","0";
			segment_para = 
						"-32767","4150","4650","4208","50",
						"4150","4450","2325","4352","0";
			batt_brand = "scudsony";
			fcc_temp = <4620 4646 4710 4747 4720 4615>;
			fcc_sf_x = <0 100 200 300 400 500>;
			fcc_sf_y = <100 96 94 92 90 88>;
			fcc_sf_cols = <6>;
			pc_sf_rows = <1>;
			pc_sf_cols = <1>;
			pc_sf_row_entries = <0>;
			pc_sf_percent = <100>;
			pc_sf_sf = <100>;
			rbatt_sf_rows = <28>;
			rbatt_sf_cols = <6>;
			rbatt_sf_percent = <100 95 90 85 80 75 70 65 60 55 50 45 40 35 30 25 20 15 10 9 8 7 6 5 4 3 2 1>;
			rbatt_sf_sf = <
			               1247 575 295 120 101 98
			               1247 575 295 120 101 98
			               1242 587 296 122 102 98
			               1221 589 301 125 104 99
			               1191 583 307 128 106 100
			               1163 577 307 134 109 102
			               1160 566 302 141 113 104
			               1157 566 289 146 119 108
			               1157 567 284 137 118 106
			               1173 574 285 123 105 101
			               1193 584 288 122 103 100
			               1226 602 300 124 105 101
			               1266 628 305 127 106 102
			               1311 663 321 132 109 104
			               1377 692 339 132 110 102
			               1472 725 357 129 105 101
			               1591 767 377 127 106 102
			               1769 821 392 128 105 102
			               2009 962 373 129 106 102
			               2137 971 375 130 106 103
			               2272 1012 386 128 107 103
			               2394 1074 397 130 108 103
			               2531 1120 425 129 109 102
			               2705 1212 443 129 107 101
			               2935 1243 445 128 107 102
			               3223 1386 475 130 108 103
			               3632 1583 557 134 109 104
			               4377 1921 697 136 113 108
			              >;
			pc_temp_ocv_rows = <29>;
			pc_temp_ocv_cols = <6>;
			pc_temp_ocv_percent = <100 95 90 85 80 75 70 65 60 55 50 45 40 35 30 25 20 15 10 9 8 7 6 5 4 3 2 1>;
			pc_temp_ocv_ocv = <
			                   4337 4335 4332 4326 4320 4312
			                   4236 4250 4254 4257 4254 4251
			                   4168 4189 4194 4201 4198 4197
			                   4107 4132 4140 4147 4144 4145
			                   4045 4076 4088 4096 4094 4095
			                   3991 4022 4037 4048 4047 4049
			                   3943 3970 3987 4003 4003 4006
			                   3901 3927 3938 3961 3962 3966
			                   3865 3887 3897 3915 3919 3921
			                   3832 3852 3863 3874 3876 3879
			                   3803 3823 3834 3845 3846 3850
			                   3779 3800 3811 3822 3823 3826
			                   3755 3781 3790 3803 3805 3807
			                   3735 3768 3776 3787 3788 3790
			                   3716 3752 3763 3770 3770 3765
			                   3699 3734 3748 3751 3746 3735
			                   3680 3714 3730 3730 3724 3714
			                   3662 3680 3699 3703 3699 3688
			                   3631 3646 3664 3677 3673 3664
			                   3626 3640 3659 3675 3671 3660
			                   3617 3634 3655 3671 3667 3657
			                   3604 3627 3648 3666 3662 3651
			                   3587 3614 3638 3657 3651 3637
			                   3563 3597 3620 3635 3625 3608
			                   3532 3560 3584 3594 3584 3567
			                   3489 3508 3530 3541 3531 3514
			                   3427 3441 3461 3471 3461 3447
			                   3340 3349 3368 3370 3364 3353
			                   3200 3200 3200 3200 3200 3200
			                  >;
		};
		coslightguangyu_4650_22k:coslightguangyu_4650_22k {
			fcc = <4650>;
			default_rbatt_mohm = <100>;
			id_identify_min = <460>;
			id_identify_max = <756>;
			id_voltage_min = <581>;
			id_voltage_max = <642>;
			vbat_max = <4352>;
			temp_para = 
						"-32767","0","-1","0","4100","0",
						"0","10","-1","1395","4352","3",
						"10","45","-1","-1","4352","3",
						"45","50","900","820","4352","3",
						"50","32767","900","0","4352","0";
			vbat_para = 
						"-32767","3400","-1","820","0",
						"3400","32767","-1","-1","0";
			segment_para = 
						"-32767","4150","4650","4208","50",
						"4150","4450","2325","4352","0";
			batt_brand = "coslightguangyu";
			fcc_temp = <4786 4782 4791 4805 4795 4758>;
			fcc_sf_x = <0 100 200 300 400 500>;
			fcc_sf_y = <100 96 94 92 90 88>;
			fcc_sf_cols = <6>;
			pc_sf_rows = <1>;
			pc_sf_cols = <1>;
			pc_sf_row_entries = <0>;
			pc_sf_percent = <100>;
			pc_sf_sf = <100>;
			rbatt_sf_rows = <28>;
			rbatt_sf_cols = <6>;
			rbatt_sf_percent = <100 95 90 85 80 75 70 65 60 55 50 45 40 35 30 25 20 15 10 9 8 7 6 5 4 3 2 1>;
			rbatt_sf_sf = <
			               1427 811 318 102 87 84
			               1425 810 318 102 87 84
			               1363 800 319 101 88 83
			               1292 781 327 103 89 84
			               1258 791 333 107 90 85
			               1100 755 371 115 94 86
			               1077 651 304 113 94 88
			               1057 663 293 120 98 90
			               1058 657 292 107 92 87
			               1093 659 286 101 88 85
			               1132 706 287 100 87 85
			               1173 759 296 101 88 85
			               1219 815 326 104 90 86
			               1270 881 366 105 91 87
			               1326 948 415 103 90 86
			               1395 1014 474 102 87 84
			               1483 1101 544 103 88 84
			               1597 1218 635 107 88 85
			               2207 1109 524 106 89 85
			               2377 1195 572 105 89 88
			               2518 1313 618 105 90 87
			               2709 1425 678 106 90 86
			               2878 1509 758 107 91 85
			               3121 1664 824 106 88 84
			               3414 1837 884 108 90 85
			               3693 2049 1007 112 90 87
			               4203 2371 1228 117 92 87
			               4822 2793 1499 141 96 87
			              >;
			pc_temp_ocv_rows = <29>;
			pc_temp_ocv_cols = <6>;
			pc_temp_ocv_percent = <100 95 90 85 80 75 70 65 60 55 50 45 40 35 30 25 20 15 10 9 8 7 6 5 4 3 2 1>;
			pc_temp_ocv_ocv = <
			                   4342 4340 4338 4332 4328 4321
			                   4235 4250 4262 4270 4268 4262
			                   4170 4184 4202 4213 4211 4206
			                   4113 4123 4149 4158 4156 4151
			                   4068 4079 4098 4106 4102 4098
			                   3966 4021 4055 4059 4053 4049
			                   3920 3935 3972 3994 3998 4003
			                   3876 3897 3923 3952 3958 3957
			                   3844 3861 3887 3907 3909 3907
			                   3823 3829 3853 3870 3870 3869
			                   3807 3812 3824 3841 3842 3841
			                   3792 3798 3802 3819 3819 3818
			                   3778 3785 3790 3800 3800 3799
			                   3764 3773 3780 3783 3784 3782
			                   3750 3758 3768 3767 3764 3758
			                   3736 3739 3753 3751 3743 3731
			                   3723 3723 3733 3732 3724 3711
			                   3704 3710 3710 3706 3700 3688
			                   3673 3691 3689 3689 3682 3670
			                   3664 3684 3686 3687 3681 3669
			                   3650 3677 3681 3685 3678 3667
			                   3636 3666 3674 3681 3675 3662
			                   3614 3646 3661 3669 3665 3651
			                   3588 3618 3638 3642 3638 3623
			                   3555 3580 3599 3600 3598 3583
			                   3505 3527 3546 3546 3546 3533
			                   3439 3456 3476 3474 3478 3466
			                   3341 3350 3369 3368 3377 3371
			                   3200 3200 3200 3200 3200 3200
			                  >;
		};
		scudatl_2600_39k:scudatl_2600_39k {
			fcc = <2600>;
			default_rbatt_mohm = <100>;
			id_identify_min = <756>;
			id_identify_max = <1075>;
			id_voltage_min = <870>;
			id_voltage_max = <954>;
			vbat_max = <4352>;
			temp_para = 
						"-32767","0","-1","0","4100","0",
						"0","10","-1","780","4352","3",
						"10","45","-1","-1","4352","3",
						"45","50","900","820","4352","3",
						"50","32767","900","0","4352","0";
			vbat_para = 
						"-32767","3400","-1","820","0",
						"3400","32767","-1","-1","0";
			segment_para = 
						"-32767","4150","2600","4208","50",
						"4150","4450","1300","4352","0";
			batt_brand = "scudatl";
			fcc_temp = <2634 2626 2627 2635 2629 2609>;
			fcc_sf_x = <0 100 200 300 400 500>;
			fcc_sf_y = <100 96 94 92 90 88>;
			fcc_sf_cols = <6>;
			pc_sf_rows = <1>;
			pc_sf_cols = <1>;
			pc_sf_row_entries = <0>;
			pc_sf_percent = <100>;
			pc_sf_sf = <100>;
			rbatt_sf_rows = <28>;
			rbatt_sf_cols = <6>;
			rbatt_sf_percent = <100 95 90 85 80 75 70 65 60 55 50 45 40 35 30 25 20 15 10 9 8 7 6 5 4 3 2 1>;
			rbatt_sf_sf = <
			               2661 1703 664 169 123 105
			               2659 1702 664 169 123 105
			               2535 1646 680 172 124 105
			               2425 1580 689 176 126 106
			               2372 1563 708 182 129 107
			               2289 1485 722 190 132 110
			               2283 1464 696 203 138 114
			               2272 1453 695 222 151 119
			               2279 1453 677 218 160 128
			               2309 1465 667 180 134 111
			               2355 1499 677 165 122 106
			               2427 1546 705 166 122 106
			               2519 1616 747 171 126 110
			               2632 1701 805 175 131 113
			               2781 1804 878 178 132 113
			               2962 1940 966 179 123 104
			               3196 2093 1085 180 124 104
			               3549 2294 1273 186 127 106
			               6592 2866 1316 194 130 108
			               7399 3201 1406 197 130 108
			               8228 3574 1544 200 134 109
			               9111 3988 1721 211 136 110
			               10094 4497 1943 220 141 112
			               11215 5101 2217 220 140 112
			               12476 5751 2520 227 142 113
			               14035 6605 2930 245 145 114
			               16347 7756 3497 292 155 113
			               22969 9461 4272 563 200 139
			              >;
			pc_temp_ocv_rows = <29>;
			pc_temp_ocv_cols = <6>;
			pc_temp_ocv_percent = <100 95 90 85 80 75 70 65 60 55 50 45 40 35 30 25 20 15 10 9 8 7 6 5 4 3 2 1>;
			pc_temp_ocv_ocv = <
			                   4328 4322 4321 4316 4309 4301
			                   4228 4233 4242 4249 4243 4237
			                   4158 4167 4181 4191 4186 4180
			                   4095 4108 4126 4136 4131 4126
			                   4038 4058 4076 4085 4080 4075
			                   3972 3994 4023 4037 4032 4028
			                   3928 3947 3971 3992 3988 3985
			                   3888 3905 3929 3954 3950 3946
			                   3855 3869 3887 3910 3911 3909
			                   3830 3839 3850 3863 3863 3860
			                   3811 3818 3823 3832 3831 3830
			                   3797 3803 3803 3810 3810 3808
			                   3786 3792 3790 3793 3793 3790
			                   3774 3783 3781 3779 3779 3777
			                   3761 3773 3771 3767 3765 3761
			                   3746 3759 3759 3753 3746 3733
			                   3730 3736 3738 3732 3725 3713
			                   3709 3709 3710 3703 3697 3687
			                   3678 3683 3676 3676 3670 3659
			                   3669 3677 3671 3674 3668 3657
			                   3660 3671 3666 3670 3664 3654
			                   3650 3663 3661 3665 3660 3649
			                   3637 3654 3653 3655 3653 3643
			                   3620 3640 3639 3635 3638 3626
			                   3593 3613 3610 3594 3599 3590
			                   3552 3566 3561 3537 3546 3539
			                   3488 3498 3493 3461 3476 3472
			                   3388 3397 3396 3356 3377 3376
			                   3200 3200 3200 3200 3200 3200
			                  >;
		};
		scudsony_4230_470k:scudsony_4230_470k {
			fcc = <4230>;
			default_rbatt_mohm = <100>;
			id_identify_min = <2022>;
			id_identify_max = <2299>;
			id_voltage_min = <2110>;
			id_voltage_max = <2258>;
			vbat_max = <4352>;
			temp_para = 
						"-32767","0","-1","0","4100","0",
						"0","10","-1","1269","4352","3",
						"10","45","-1","-1","4352","3",
						"45","50","900","820","4352","3",
						"50","32767","900","0","4352","0";
			vbat_para = 
						"-32767","3400","-1","820","0",
						"3400","32767","-1","-1","0";
			segment_para = 
						"-32767","4150","4230","4208","50",
						"4150","4450","2115","4352","0";
			batt_brand = "scudsony";
			fcc_temp = <4194 4229 4277 4361 4307 4249>;
			fcc_sf_x = <0 100 200 300 400 500>;
			fcc_sf_y = <100 96 94 92 90 88>;
			fcc_sf_cols = <6>;
			pc_sf_rows = <1>;
			pc_sf_cols = <1>;
			pc_sf_row_entries = <0>;
			pc_sf_percent = <100>;
			pc_sf_sf = <100>;
			rbatt_sf_rows = <28>;
			rbatt_sf_cols = <6>;
			rbatt_sf_percent = <100 95 90 85 80 75 70 65 60 55 50 45 40 35 30 25 20 15 10 9 8 7 6 5 4 3 2 1>;
			rbatt_sf_sf = <
			               832 377 208 101 85 80
			               832 377 208 101 85 80
			               818 395 225 107 88 81
			               819 379 237 113 92 83
			               830 373 246 119 95 85
			               851 377 247 127 99 87
			               871 389 220 136 104 89
			               884 399 214 140 111 95
			               915 405 216 125 113 98
			               928 414 220 106 93 84
			               944 422 229 104 88 83
			               958 432 236 107 89 83
			               1026 440 241 110 92 84
			               1090 447 246 113 95 86
			               1161 460 254 114 95 84
			               1261 469 264 111 89 83
			               1406 460 261 107 88 83
			               1626 521 253 104 87 82
			               2139 671 261 103 87 83
			               2093 593 263 104 88 84
			               1661 618 269 104 88 84
			               1799 647 278 107 90 83
			               1992 678 291 107 90 83
			               2287 705 296 107 87 81
			               2658 746 304 105 87 81
			               3498 880 328 106 89 83
			               5073 1189 399 107 92 84
			               9013 1936 534 106 96 88
			              >;
			pc_temp_ocv_rows = <29>;
			pc_temp_ocv_cols = <6>;
			pc_temp_ocv_percent = <100 95 90 85 80 75 70 65 60 55 50 45 40 35 30 25 20 15 10 9 8 7 6 5 4 3 2 1>;
			pc_temp_ocv_ocv = <
			                   4339 4337 4334 4329 4320 4310
			                   4258 4264 4265 4265 4257 4250
			                   4188 4206 4207 4208 4201 4195
			                   4128 4140 4152 4153 4147 4142
			                   4072 4082 4099 4100 4095 4091
			                   4019 4030 4046 4051 4047 4043
			                   3969 3983 3987 4006 4003 4000
			                   3923 3940 3941 3961 3962 3961
			                   3885 3900 3902 3914 3920 3920
			                   3850 3866 3869 3873 3874 3873
			                   3816 3837 3841 3843 3844 3844
			                   3779 3813 3817 3821 3821 3821
			                   3758 3792 3797 3802 3803 3802
			                   3742 3774 3780 3786 3787 3785
			                   3730 3761 3767 3771 3770 3764
			                   3717 3745 3756 3754 3747 3735
			                   3705 3714 3736 3732 3723 3712
			                   3688 3695 3705 3701 3694 3682
			                   3663 3674 3674 3675 3669 3658
			                   3658 3670 3670 3672 3666 3656
			                   3649 3663 3665 3667 3662 3652
			                   3638 3655 3659 3662 3657 3646
			                   3621 3643 3649 3652 3644 3631
			                   3600 3621 3629 3630 3615 3601
			                   3564 3581 3589 3589 3571 3558
			                   3517 3525 3534 3536 3516 3504
			                   3448 3451 3466 3466 3446 3435
			                   3344 3354 3370 3366 3350 3343
			                   3200 3200 3200 3200 3200 3200
			                  >;
		};
		scudatl_2620_10k:scudatl_2620_10k {
			fcc = <2620>;
			default_rbatt_mohm = <100>;
			id_identify_min = <0>;
			id_identify_max = <460>;
			id_voltage_min = <303>;
			id_voltage_max = <339>;
			vbat_max = <4352>;
			temp_para = 
						"-32767","0","-1","0","4100","0",
						"0","10","-1","786","4352","3",
						"10","45","-1","-1","4352","3",
						"45","50","900","820","4352","3",
						"50","32767","900","0","4352","0";
			vbat_para = 
						"-32767","3400","-1","820","0",
						"3400","32767","-1","-1","0";
			segment_para = 
						"-32767","4150","2620","4208","50",
						"4150","4450","1310","4352","0";
			batt_brand = "scudatl";
			fcc_temp = <2662 2661 2662 2689 2658 2642>;
			fcc_sf_x = <0 100 200 300 400 500>;
			fcc_sf_y = <100 96 94 92 90 88>;
			fcc_sf_cols = <6>;
			pc_sf_rows = <1>;
			pc_sf_cols = <1>;
			pc_sf_row_entries = <0>;
			pc_sf_percent = <100>;
			pc_sf_sf = <100>;
			rbatt_sf_rows = <28>;
			rbatt_sf_cols = <6>;
			rbatt_sf_percent = <100 95 90 85 80 75 70 65 60 55 50 45 40 35 30 25 20 15 10 9 8 7 6 5 4 3 2 1>;
			rbatt_sf_sf = <
			               2234 1112 442 129 97 87
			               2231 1112 442 129 97 87
			               2042 1101 450 130 99 87
			               1904 1070 454 133 101 89
			               1871 1106 468 138 105 91
			               1709 1055 513 147 108 93
			               1690 968 466 156 114 97
			               1678 971 468 173 124 101
			               1675 958 434 170 134 108
			               1701 966 412 131 106 91
			               1748 990 413 122 98 88
			               1818 1044 426 125 99 88
			               1906 1116 452 130 103 91
			               2026 1209 496 134 110 96
			               2175 1324 552 136 112 98
			               2355 1479 626 134 101 89
			               2579 1671 728 133 102 90
			               2863 1899 896 138 104 92
			               5121 2230 929 140 109 94
			               5847 2558 1008 147 109 93
			               6546 2885 1131 155 111 97
			               7290 3267 1273 159 114 98
			               8079 3666 1464 167 117 98
			               8886 4097 1679 169 116 94
			               9830 4614 1844 181 119 98
			               10934 5250 2175 208 124 99
			               12353 6119 2642 299 132 102
			               14750 7411 3369 879 211 145
			              >;
			pc_temp_ocv_rows = <29>;
			pc_temp_ocv_cols = <6>;
			pc_temp_ocv_percent = <100 95 90 85 80 75 70 65 60 55 50 45 40 35 30 25 20 15 10 9 8 7 6 5 4 3 2 1>;
			pc_temp_ocv_ocv = <
			                   4330 4328 4327 4330 4317 4310
			                   4238 4248 4254 4263 4253 4247
			                   4171 4185 4194 4204 4195 4189
			                   4109 4125 4139 4148 4140 4134
			                   4061 4082 4089 4095 4088 4083
			                   3977 4019 4041 4047 4040 4034
			                   3930 3955 3981 3998 3995 3991
			                   3889 3914 3942 3959 3955 3951
			                   3854 3874 3895 3915 3915 3911
			                   3829 3842 3856 3868 3866 3863
			                   3812 3817 3827 3837 3836 3833
			                   3800 3802 3806 3814 3813 3811
			                   3790 3792 3792 3796 3796 3792
			                   3781 3784 3783 3781 3781 3778
			                   3769 3773 3775 3768 3766 3761
			                   3756 3760 3763 3753 3745 3732
			                   3739 3740 3742 3731 3725 3712
			                   3716 3716 3712 3702 3699 3687
			                   3684 3684 3679 3678 3672 3660
			                   3676 3678 3674 3675 3670 3658
			                   3667 3672 3670 3671 3667 3654
			                   3658 3666 3664 3664 3662 3650
			                   3647 3657 3655 3651 3654 3641
			                   3628 3642 3641 3620 3634 3617
			                   3598 3612 3608 3574 3595 3578
			                   3553 3563 3558 3513 3543 3526
			                   3486 3494 3489 3434 3475 3458
			                   3394 3402 3395 3330 3379 3361
			                   3200 3200 3200 3200 3200 3200
			                  >;
		};
		sunwodaatl_3000_10k:sunwodaatl_3000_10k {
			fcc = <3000>;
			default_rbatt_mohm = <100>;
			id_identify_min = <0>;
			id_identify_max = <460>;
			id_voltage_min = <303>;
			id_voltage_max = <339>;
			vbat_max = <4352>;
			temp_para = 
						"-32767","0","-1","0","4100","0",
						"0","10","-1","900","4352","3",
						"10","45","-1","-1","4352","3",
						"45","50","900","820","4352","3",
						"50","32767","900","0","4352","0";
			vbat_para = 
						"-32767","3400","-1","820","0",
						"3400","32767","-1","-1","0";
			segment_para = 
						"-32767","4150","3000","4208","50",
						"4150","4450","1500","4352","0";
			batt_brand = "sunwodaatl";
			fcc_temp = <3073 3068 3057 3065 3059 3040>;
			fcc_sf_x = <0 100 200 300 400 500>;
			fcc_sf_y = <100 96 94 92 90 88>;
			fcc_sf_cols = <6>;
			pc_sf_rows = <1>;
			pc_sf_cols = <1>;
			pc_sf_row_entries = <0>;
			pc_sf_percent = <100>;
			pc_sf_sf = <100>;
			rbatt_sf_rows = <28>;
			rbatt_sf_cols = <6>;
			rbatt_sf_percent = <100 95 90 85 80 75 70 65 60 55 50 45 40 35 30 25 20 15 10 9 8 7 6 5 4 3 2 1>;
			rbatt_sf_sf = <
			               2282 1151 543 163 124 107
			               2278 1151 543 163 124 107
			               2096 1151 554 167 126 108
			               2003 1123 556 171 129 110
			               1963 1144 577 176 131 112
			               1833 1109 583 186 135 115
			               1829 1049 552 195 141 118
			               1820 1048 544 210 151 123
			               1816 1044 522 203 157 129
			               1835 1042 507 167 132 112
			               1879 1068 511 158 123 109
			               1939 1113 523 161 124 110
			               2018 1175 549 164 128 113
			               2124 1250 590 166 132 117
			               2253 1344 637 170 131 116
			               2405 1473 699 170 124 109
			               2599 1637 785 170 125 108
			               2878 1839 932 176 128 110
			               5588 2276 962 179 129 112
			               6231 2492 1034 184 129 112
			               6930 2772 1120 190 132 114
			               7725 3082 1225 198 135 116
			               8605 3444 1381 199 142 117
			               9669 3908 1569 208 137 114
			               11042 4500 1776 214 137 114
			               12647 5237 2107 262 147 116
			               14469 6414 2632 460 183 133
			               15291 8580 3373 574 267 143
			              >;
			pc_temp_ocv_rows = <29>;
			pc_temp_ocv_cols = <6>;
			pc_temp_ocv_percent = <100 95 90 85 80 75 70 65 60 55 50 45 40 35 30 25 20 15 10 9 8 7 6 5 4 3 2 1>;
			pc_temp_ocv_ocv = <
			                   4325 4327 4320 4318 4313 4307
			                   4234 4249 4251 4253 4249 4244
			                   4162 4186 4192 4195 4191 4186
			                   4108 4125 4135 4140 4136 4131
			                   4058 4079 4087 4087 4084 4079
			                   3974 4019 4034 4039 4035 4031
			                   3928 3955 3976 3992 3990 3986
			                   3887 3913 3932 3952 3950 3947
			                   3852 3875 3889 3908 3909 3908
			                   3825 3840 3851 3861 3862 3860
			                   3808 3815 3824 3832 3831 3830
			                   3795 3799 3803 3810 3810 3808
			                   3783 3787 3789 3793 3792 3790
			                   3773 3777 3780 3778 3778 3775
			                   3762 3765 3771 3766 3763 3758
			                   3748 3752 3757 3752 3743 3732
			                   3731 3734 3736 3731 3722 3710
			                   3709 3711 3709 3701 3695 3685
			                   3676 3681 3677 3675 3669 3658
			                   3667 3675 3673 3673 3666 3655
			                   3657 3669 3668 3668 3662 3652
			                   3645 3663 3663 3662 3658 3647
			                   3628 3653 3655 3652 3651 3640
			                   3603 3635 3641 3630 3633 3621
			                   3564 3603 3609 3588 3593 3585
			                   3507 3550 3558 3533 3541 3534
			                   3433 3475 3491 3470 3474 3469
			                   3328 3370 3399 3376 3380 3375
			                   3200 3200 3200 3200 3200 3200
			                  >;
		};
		scudatl_2520_200k:scudatl_2520_200k {
			fcc = <2520>;
			default_rbatt_mohm = <100>;
			id_identify_min = <1702>;
			id_identify_max = <2022>;
			id_voltage_min = <1797>;
			id_voltage_max = <1934>;
			vbat_max = <4352>;
			temp_para = 
						"-32767","0","-1","0","4100","0",
						"0","10","-1","756","4352","3",
						"10","45","-1","-1","4352","3",
						"45","50","900","820","4352","3",
						"50","32767","900","0","4352","0";
			vbat_para = 
						"-32767","3400","-1","820","0",
						"3400","32767","-1","-1","0";
			segment_para = 
						"-32767","4150","2520","4208","50",
						"4150","4450","1260","4352","0";
			batt_brand = "scudatl";
			fcc_temp = <2567 2570 2563 2567 2562 2551>;
			fcc_sf_x = <0 100 200 300 400 500>;
			fcc_sf_y = <100 96 94 92 90 88>;
			fcc_sf_cols = <6>;
			pc_sf_rows = <1>;
			pc_sf_cols = <1>;
			pc_sf_row_entries = <0>;
			pc_sf_percent = <100>;
			pc_sf_sf = <100>;
			rbatt_sf_rows = <28>;
			rbatt_sf_cols = <6>;
			rbatt_sf_percent = <100 95 90 85 80 75 70 65 60 55 50 45 40 35 30 25 20 15 10 9 8 7 6 5 4 3 2 1>;
			rbatt_sf_sf = <
			               2261 940 421 138 105 94
			               2259 940 421 138 105 94
			               2105 958 429 140 106 94
			               1965 961 446 143 108 96
			               1899 979 465 148 111 97
			               1776 963 494 156 115 99
			               1770 899 475 168 121 103
			               1768 894 453 187 131 108
			               1764 892 423 185 141 115
			               1783 908 413 145 113 99
			               1810 938 415 137 106 96
			               1857 980 426 138 107 96
			               1939 1043 444 142 109 99
			               2040 1122 476 146 114 101
			               2170 1226 522 148 115 104
			               2326 1363 579 145 107 95
			               2516 1473 646 144 106 96
			               2778 1760 755 150 108 96
			               3897 2034 819 157 114 99
			               4598 2194 817 158 115 101
			               5255 2466 884 163 115 102
			               6005 2802 968 171 117 103
			               6883 3228 1090 177 121 103
			               7900 3729 1270 180 120 102
			               9100 4267 1500 213 121 103
			               10744 4925 1800 231 143 114
			               13193 6089 2171 236 209 152
			               18905 8194 2705 449 230 177
			              >;
			pc_temp_ocv_rows = <29>;
			pc_temp_ocv_cols = <6>;
			pc_temp_ocv_percent = <100 95 90 85 80 75 70 65 60 55 50 45 40 35 30 25 20 15 10 9 8 7 6 5 4 3 2 1>;
			pc_temp_ocv_ocv = <
			                   4329 4328 4325 4320 4316 4311
			                   4238 4246 4251 4254 4251 4246
			                   4169 4183 4190 4196 4193 4188
			                   4107 4126 4136 4140 4137 4133
			                   4052 4076 4086 4088 4085 4081
			                   3982 4020 4037 4040 4037 4033
			                   3941 3960 3983 3994 3992 3989
			                   3906 3917 3936 3955 3953 3949
			                   3871 3878 3891 3911 3913 3911
			                   3842 3847 3856 3863 3864 3862
			                   3819 3823 3829 3833 3833 3831
			                   3802 3805 3808 3812 3811 3809
			                   3791 3794 3793 3795 3794 3791
			                   3780 3785 3783 3781 3780 3777
			                   3769 3777 3775 3769 3766 3762
			                   3755 3768 3764 3755 3746 3735
			                   3737 3736 3743 3734 3726 3714
			                   3716 3711 3712 3704 3698 3687
			                   3689 3684 3679 3677 3670 3659
			                   3682 3677 3675 3674 3667 3657
			                   3675 3671 3670 3670 3664 3654
			                   3668 3664 3664 3665 3659 3649
			                   3660 3655 3656 3656 3652 3642
			                   3647 3642 3642 3635 3634 3624
			                   3620 3614 3615 3596 3598 3586
			                   3571 3562 3569 3541 3545 3534
			                   3493 3483 3502 3467 3478 3468
			                   3377 3375 3400 3366 3380 3370
			                   3200 3200 3200 3200 3200 3200
			                  >;
		};
		scudsamsung_4650_200k:scudsamsung_4650_200k {
			fcc = <4650>;
			default_rbatt_mohm = <100>;
			id_identify_min = <1702>;
			id_identify_max = <2022>;
			id_voltage_min = <1797>;
			id_voltage_max = <1934>;
			vbat_max = <4352>;
			temp_para = 
						"-32767","0","-1","0","4100","0",
						"0","10","-1","1395","4352","3",
						"10","45","-1","-1","4352","3",
						"45","50","900","820","4352","3",
						"50","32767","900","0","4352","0";
			vbat_para = 
						"-32767","3400","-1","820","0",
						"3400","32767","-1","-1","0";
			segment_para = 
						"-32767","4150","4650","4208","50",
						"4150","4450","2325","4352","0";
			batt_brand = "scudsamsung";
			fcc_temp = <4895 4896 4896 4944 4905 4873>;
			fcc_sf_x = <0 100 200 300 400 500>;
			fcc_sf_y = <100 96 94 92 90 88>;
			fcc_sf_cols = <6>;
			pc_sf_rows = <1>;
			pc_sf_cols = <1>;
			pc_sf_row_entries = <0>;
			pc_sf_percent = <100>;
			pc_sf_sf = <100>;
			rbatt_sf_rows = <28>;
			rbatt_sf_cols = <6>;
			rbatt_sf_percent = <100 95 90 85 80 75 70 65 60 55 50 45 40 35 30 25 20 15 10 9 8 7 6 5 4 3 2 1>;
			rbatt_sf_sf = <
			               1601 980 494 117 87 79
			               1594 979 494 117 87 79
			               1474 957 495 117 87 79
			               1381 918 495 119 87 80
			               1330 908 506 123 91 81
			               1206 853 504 128 93 83
			               1196 776 438 134 96 84
			               1185 780 436 145 104 88
			               1186 771 424 138 106 89
			               1211 771 419 118 94 83
			               1250 797 416 113 88 80
			               1305 845 427 113 89 81
			               1365 898 459 115 91 82
			               1432 959 504 117 94 85
			               1506 1029 562 117 93 83
			               1597 1099 626 118 90 81
			               1696 1183 693 119 88 81
			               1819 1290 803 119 89 81
			               3002 1483 745 116 91 82
			               3077 1593 795 118 89 81
			               3297 1703 860 121 90 81
			               3475 1804 923 121 90 83
			               3632 1940 1007 123 91 83
			               3822 2074 1122 123 91 81
			               4120 2227 1167 124 89 81
			               4372 2419 1254 131 91 83
			               4759 2715 1376 136 93 81
			               5578 3074 1620 145 97 84
			              >;
			pc_temp_ocv_rows = <29>;
			pc_temp_ocv_cols = <6>;
			pc_temp_ocv_percent = <100 95 90 85 80 75 70 65 60 55 50 45 40 35 30 25 20 15 10 9 8 7 6 5 4 3 2 1>;
			pc_temp_ocv_ocv = <
			                   4336 4334 4331 4327 4319 4312
			                   4229 4242 4251 4263 4258 4253
			                   4162 4177 4191 4206 4201 4197
			                   4101 4119 4137 4152 4147 4143
			                   4050 4074 4090 4100 4095 4091
			                   3961 4011 4037 4050 4045 4043
			                   3918 3938 3963 3998 3999 3998
			                   3878 3902 3922 3960 3962 3958
			                   3843 3864 3884 3916 3918 3915
			                   3820 3832 3850 3870 3871 3870
			                   3802 3811 3821 3839 3840 3839
			                   3788 3797 3800 3816 3817 3816
			                   3774 3784 3788 3798 3799 3797
			                   3761 3771 3777 3782 3784 3782
			                   3747 3756 3766 3770 3768 3763
			                   3734 3741 3750 3757 3752 3740
			                   3718 3726 3730 3739 3733 3719
			                   3700 3712 3712 3709 3705 3691
			                   3668 3690 3690 3688 3682 3669
			                   3655 3685 3686 3687 3681 3668
			                   3646 3679 3682 3686 3680 3667
			                   3635 3670 3675 3683 3678 3665
			                   3618 3658 3665 3677 3674 3661
			                   3594 3637 3653 3657 3664 3646
			                   3568 3607 3626 3614 3634 3611
			                   3525 3563 3582 3553 3583 3559
			                   3466 3503 3515 3465 3513 3490
			                   3376 3402 3407 3354 3411 3386
			                   3200 3200 3200 3200 3200 3200
			                  >;
		};
	};
};
